# ESP32-H2 register map
Vendor: ESPRESSIF SYSTEMS (SHANGHAI) CO., LTD.; Series: ESP32 H-Series; File version: 12
CPU: RV32IMAC r0p0, little endian, no MPU, no FPU, 0 interrupt priority bits
Address unit: 32 bits
Registers are 32-bit, read-write, reset 0x0 unless marked. A register's access mark holds for its fields unless they carry their own. Offsets are from the block's base; [hi:lo] are bit positions; lines under a group give offsets from that group; {n}, {i} and the like mark numbered series; 'fields as' and 'values as' point back to an identical list.

## UHCI0 — Universal Host Controller Interface 0
Base 0x60006000
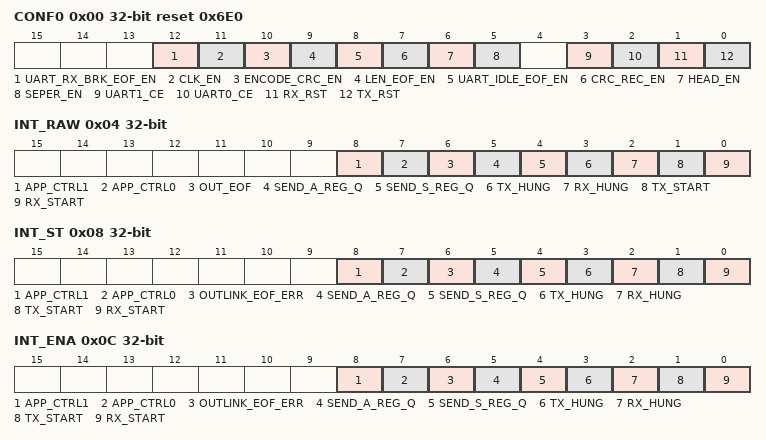
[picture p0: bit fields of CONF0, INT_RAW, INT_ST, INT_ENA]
0x00 CONF0 reset 0x6E0 — a
  [12] UART_RX_BRK_EOF_EN — If this bit is set to 1 UHCI will end payload receive process when NULL frame is received by UART.
  [11] CLK_EN — 1'b1: Force clock on for register. 1'b0: Support clock only when application writes registers.
  [10] ENCODE_CRC_EN — Set this bit to enable data integrity checking by appending a 16 bit CCITT-CRC to end of the payload.
  [9] LEN_EOF_EN — If this bit is set to 1 UHCI decoder receiving payload data is end when the receiving byte count has reached the specified value. The value is payload length indicated by UHCI packet header when UHCI_HEAD_EN is 1 or the value is configuration value when UHCI_HEAD_EN is 0. If this bit is set to 0 UHCI decoder receiving payload data is end when 0xc0 is received.
  [8] UART_IDLE_EOF_EN — If this bit is set to 1 UHCI will end the payload receiving process when UART has been in idle state.
  [7] CRC_REC_EN — Set this bit to enable UHCI to receive the 16 bit CRC.
  [6] HEAD_EN — Set this bit to encode the data packet with a formatting header.
  [5] SEPER_EN — Set this bit to separate the data frame using a special char.
  [3] UART1_CE — Set this bit to link up HCI and UART1.
  [2] UART0_CE — Set this bit to link up HCI and UART0.
  [1] RX_RST — Write 1 then write 0 to this bit to reset encode state machine.
  [0] TX_RST — Write 1 then write 0 to this bit to reset decode state machine.
0x04 INT_RAW — a
  [8] APP_CTRL1 — Soft control int raw bit.
  [7] APP_CTRL0 — Soft control int raw bit.
  [6] OUT_EOF — This is the interrupt raw bit. Triggered when there are some errors in EOF in the
  [5] SEND_A_REG_Q — a
  [4] SEND_S_REG_Q — a
  [3] TX_HUNG — a
  [2] RX_HUNG — a
  [1] TX_START — a
  [0] RX_START — a
0x08 INT_ST ro — a
  [8] APP_CTRL1 — a
  [7] APP_CTRL0 — a
  [6] OUTLINK_EOF_ERR — a
  [5] SEND_A_REG_Q — a
  [4] SEND_S_REG_Q — a
  [3] TX_HUNG — a
  [2] RX_HUNG — a
  [1] TX_START — a
  [0] RX_START — a
0x0C INT_ENA — a
  fields as INT_ST
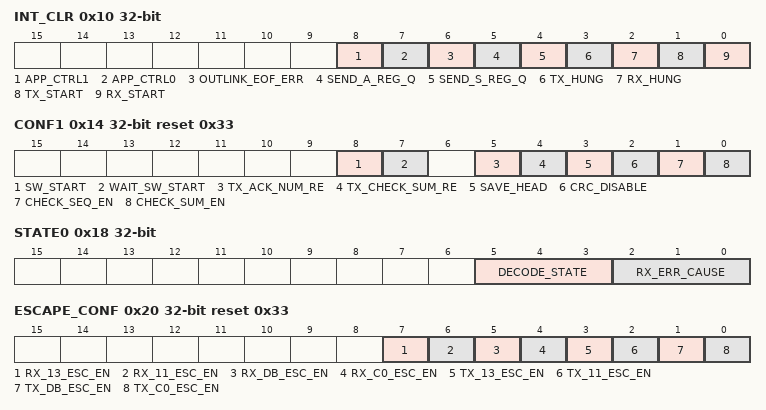
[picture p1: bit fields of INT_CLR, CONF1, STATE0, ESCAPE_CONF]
0x10 INT_CLR wo — a
  [8] APP_CTRL1 write-1-clears — a
  [7] APP_CTRL0 write-1-clears — a
  [6] OUTLINK_EOF_ERR write-1-clears — a
  [5] SEND_A_REG_Q write-1-clears — a
  [4] SEND_S_REG_Q write-1-clears — a
  [3] TX_HUNG write-1-clears — a
  [2] RX_HUNG write-1-clears — a
  [1] TX_START write-1-clears — a
  [0] RX_START write-1-clears — a
0x14 CONF1 access per field reset 0x33 — a
  [8] SW_START wo — a
  [7] WAIT_SW_START rw — a
  [5] TX_ACK_NUM_RE rw — a
  [4] TX_CHECK_SUM_RE rw — a
  [3] SAVE_HEAD rw — a
  [2] CRC_DISABLE rw — a
  [1] CHECK_SEQ_EN rw — a
  [0] CHECK_SUM_EN rw — a
0x18 STATE0 ro — a
  [5:3] DECODE_STATE — a
  [2:0] RX_ERR_CAUSE — a
0x1C STATE1 ro — a
  [2:0] ENCODE_STATE
0x20 ESCAPE_CONF reset 0x33 — a
  [7] RX_13_ESC_EN — a
  [6] RX_11_ESC_EN — a
  [5] RX_DB_ESC_EN — a
  [4] RX_C0_ESC_EN — a
  [3] TX_13_ESC_EN — a
  [2] TX_11_ESC_EN — a
  [1] TX_DB_ESC_EN — a
  [0] TX_C0_ESC_EN — a
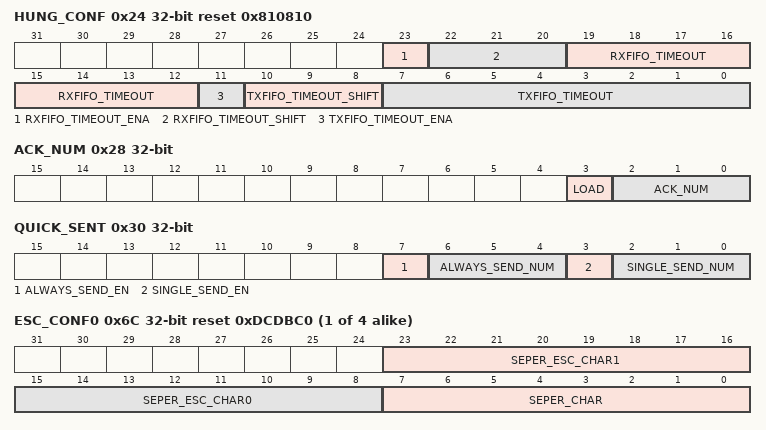
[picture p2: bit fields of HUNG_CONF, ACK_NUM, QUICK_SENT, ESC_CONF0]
0x24 HUNG_CONF reset 0x810810 — a
  [23] RXFIFO_TIMEOUT_ENA — a
  [22:20] RXFIFO_TIMEOUT_SHIFT — a
  [19:12] RXFIFO_TIMEOUT — a
  [11] TXFIFO_TIMEOUT_ENA — a
  [10:8] TXFIFO_TIMEOUT_SHIFT — a
  [7:0] TXFIFO_TIMEOUT — a
0x28 ACK_NUM access per field — a
  [3] LOAD wo — a
  [2:0] ACK_NUM rw — a
0x2C RX_HEAD ro — a
0x30 QUICK_SENT access per field — a
  [7] ALWAYS_SEND_EN rw — a
  [6:4] ALWAYS_SEND_NUM rw — a
  [3] SINGLE_SEND_EN wo — a
  [2:0] SINGLE_SEND_NUM rw — a
{0x34+8i} REG_Q{i} (i=0..6) group — Cluster REG_Q{i}, containing REG_Q?_WORD0, REG_Q?_WORD1
  0x00 WORD0 — a
    [31:0] SEND_WORD
  0x04 WORD1 — a
    [31:0] SEND_WORD
{0x6C+4i} ESC_CONF{i} (i=0..3) reset 0xDCDBC0 — a
  [23:16] SEPER_ESC_CHAR1 — a
  [15:8] SEPER_ESC_CHAR0 — a
  [7:0] SEPER_CHAR — a
0x7C PKT_THRES reset 0x80 — a
  [12:0] PKT_THRS
0x80 DATE — a
